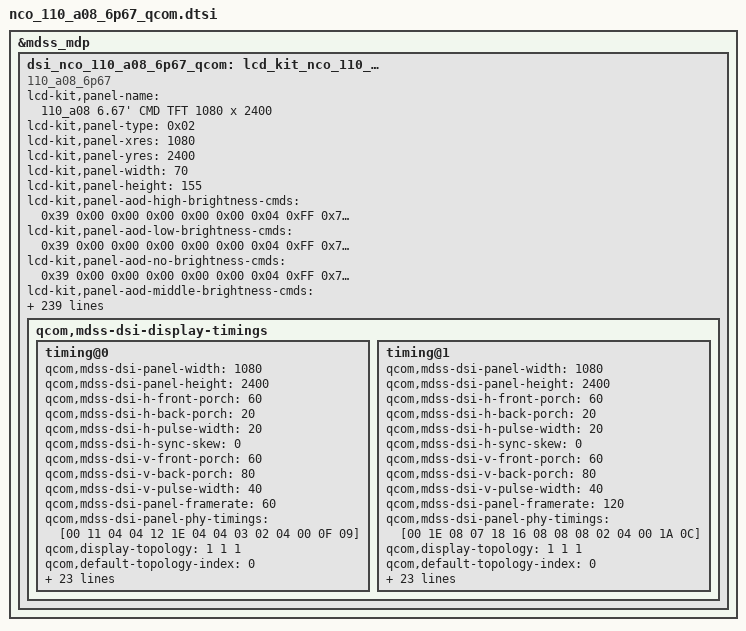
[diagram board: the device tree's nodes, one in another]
/* Copyright (c) 2013, The Linux Foundation. All rights reserved.
 *
 * This program is free software; you can redistribute it and/or modify
 * it under the terms of the GNU General Public License version 2 and
 * only version 2 as published by the Free Software Foundation.
 *
 * This program is distributed in the hope that it will be useful,
 * but WITHOUT ANY WARRANTY; without even the implied warranty of
 * MERCHANTABILITY or FITNESS FOR A PARTICULAR PURPOSE.  See the
 * GNU General Public License for more details.
 */

/*-------------------------------------------------------------------------
 * This file is autogenerated file using gcdb parser. Please do not edit it.
 * Update input XML file to add a new entry or update variable in this file
 * VERSION = 1.1
 *-----------------------------------------------------------------------*/
&mdss_mdp {
	dsi_nco_110_a08_6p67_qcom: lcd_kit_nco_110_a08_6p67_qcom {
		compatible = "110_a08_6p67";
		lcd-kit,panel-name = "110_a08 6.67' CMD TFT 1080 x 2400";
		lcd-kit,panel-type = <0x02>;
		lcd-kit,panel-xres = <1080>;
		lcd-kit,panel-yres = <2400>;
		lcd-kit,panel-width = <70>;
		lcd-kit,panel-height = <155>;
		lcd-kit,panel-aod-high-brightness-cmds = <0x39 0x00 0x00 0x00 0x00 0x00 0x04 0xFF 0x78 0x38 0x0C
		0x15 0x00 0x00 0x00 0x00 0x00 0x02 0xBE 0x00
		0x15 0x00 0x00 0x00 0x00 0x00 0x02 0x36 0x20
		0x15 0x00 0x00 0x00 0x00 0x00 0x02 0x34 0xF2
		0x39 0x01 0x00 0x00 0x00 0x00 0x04 0xFF 0x78 0x38 0x00>;
		lcd-kit,panel-aod-low-brightness-cmds = <0x39 0x00 0x00 0x00 0x00 0x00 0x04 0xFF 0x78 0x38 0x0C
		0x15 0x00 0x00 0x00 0x00 0x00 0x02 0xBE 0x02
		0x15 0x00 0x00 0x00 0x00 0x00 0x02 0x36 0x20
		0x15 0x00 0x00 0x00 0x00 0x00 0x02 0x34 0xF2
		0x39 0x01 0x00 0x00 0x00 0x00 0x04 0xFF 0x78 0x38 0x00>;
		lcd-kit,panel-aod-no-brightness-cmds = <0x39 0x00 0x00 0x00 0x00 0x00 0x04 0xFF 0x78 0x38 0x0C
		0x15 0x00 0x00 0x00 0x00 0x00 0x02 0x34 0xFF
		0x15 0x00 0x00 0x00 0x00 0x00 0x02 0x36 0xFF
		0x39 0x01 0x00 0x00 0x00 0x00 0x04 0xFF 0x78 0x38 0x00>;
		lcd-kit,panel-aod-middle-brightness-cmds = <0x39 0x00 0x00 0x00 0x00 0x00 0x04 0xFF 0x78 0x38 0x0C
		0x15 0x00 0x00 0x00 0x00 0x00 0x02 0xBE 0x01
		0x15 0x00 0x00 0x00 0x00 0x00 0x02 0x36 0x20
		0x15 0x00 0x00 0x00 0x00 0x00 0x02 0x34 0xF2
		0x39 0x01 0x00 0x00 0x00 0x00 0x04 0xFF 0x78 0x38 0x00>;
		lcd-kit,panel-aod-high-brightness-cmds-state = "dsi_lp_mode";
		lcd-kit,panel-aod-low-brightness-cmds-state = "dsi_lp_mode";
		lcd-kit,panel-aod-no-brightness-cmds-state = "dsi_lp_mode";
		lcd-kit,panel-aod-middle-brightness-cmds-state = "dsi_lp_mode";
		lcd-kit,pcd-check-reg-cmds = <0x01>;
		lcd-kit,check-reg-on-cmds = <0x06 0x01 0x00 0x00 0x0a 0x00 0x01 0x0a>;
		lcd-kit,check-reg-on-value = <0x9c>;
		lcd-kit,check-aod-reg-on-cmds = <0x06 0x01 0x00 0x00 0x0a 0x00 0x01 0x0a>;
		lcd-kit,check-aod-reg-on-value = <0xdc>;
		lcd-kit,check-reg-off-cmds = <0x06 0x01 0x00 0x00 0x0a 0x00 0x01 0x0a>;
		lcd-kit,check-reg-off-value = <0x08>;
		lcd-kit,check-reg-on-cmds-state = "dsi_lp_mode";
		lcd-kit,check-aod-reg-on-cmds-state = "dsi_lp_mode";
		lcd-kit,check-reg-off-cmds-state = "dsi_lp_mode";
		lcd-kit,pcd-check-reg-value = <0x01>;
		lcd-kit,pcd-errflag-check-support = <0>;
		lcd-kit,checksum-enable-cmds = <0x39 0x01 0x00 0x00 0x14 0x00 0x05 0xFF 0xAA 0x55 0xA5 0x80
		0x15 0x01 0x00 0x00 0x0a 0x00 0x02 0xF2 0x03>;
		lcd-kit,checksum-enable-cmds-state = "dsi_lp_mode";
		lcd-kit,checksum-disable-cmds = <0x39 0x01 0x00 0x00 0x14 0x00 0x05 0xFF 0xAA 0x55 0xA5 0x80
		0x15 0x01 0x00 0x00 0x0a 0x00 0x02 0xF2 0x00>;
		lcd-kit,checksum-disable-cmds-state = "dsi_lp_mode";
		lcd-kit,checksum-cmds = <0x39 0x01 0x00 0x00 0x14 0x00 0x05 0xFF 0xAA 0x55 0xA5 0x80
		0x15 0x01 0x00 0x00 0x0a 0x00 0x02 0x6F 0x01
		0x14 0x01 0x00 0x00 0x0a 0x00 0x08 0xF2 0x00 0x00 0x00 0x00 0x00 0x00 0x00>;
		lcd-kit,checksum-cmds-state = "dsi_lp_mode";
		lcd-kit,checksum-value = <0x06 0xf2 0x7d 0x83 0x91 0xe7 0x4c 0x2a
		0xba 0xeb 0x79 0x7c 0xe4 0xb4 0xcb 0x62
		0x97 0x89 0xd0 0x7a 0xc4 0xee 0xf7 0x69>;
		lcd-kit,hor-line-cmds = <0x39 0x01 0x00 0x00 0x00 0x00 0x04 0xFF 0x78 0x38 0x00
		0x05 0x01 0x00 0x00 0x64 0x00 0x01 0x28
		0x39 0x01 0x00 0x00 0x00 0x00 0x04 0xFF 0x78 0x38 0x05
		0x15 0x01 0x00 0x00 0x00 0x00 0x02 0x2E 0x4D
		0x15 0x01 0x00 0x00 0x00 0x00 0x02 0x34 0x4D
		0x15 0x01 0x00 0x00 0x00 0x00 0x02 0x73 0x0B
		0x15 0x01 0x00 0x00 0x00 0x00 0x02 0x77 0x0B
		0x15 0x01 0x00 0x00 0x00 0x00 0x02 0x03 0x4E
		0x15 0x01 0x00 0x00 0x00 0x00 0x02 0x20 0xAB
		0x15 0x01 0x00 0x00 0x00 0x00 0x02 0x23 0xAE
		0x39 0x01 0x00 0x00 0x00 0x00 0x04 0xFF 0x78 0x38 0x00
		0x39 0x01 0x00 0x00 0x00 0x00 0x03 0x51 0x0D 0xBB
		0x05 0x01 0x00 0x00 0x78 0x00 0x01 0x11
		0x05 0x01 0x00 0x00 0x64 0x00 0x01 0x29>;
		lcd-kit,hor-line-cmds-state = "dsi_lp_mode";
		lcd-kit,pcd-read-cmds = <0x39 0x01 0x00 0x00 0x00 0x00 0x04 0xFF 0x78 0x38 0x1B
		0x15 0x01 0x00 0x00 0x00 0x00 0x02 0xF1 0x10
		0x06 0x01 0x00 0x00 0x00 0x00 0x01 0xF7
		0x39 0x01 0x00 0x00 0x00 0x00 0x04 0xFF 0x78 0x38 0x00
		0x39 0x01 0x00 0x00 0x00 0x00 0x04 0xFF 0x78 0x38 0x1B
		0x15 0x01 0x00 0x00 0x00 0x00 0x02 0xF1 0x00
		0x39 0x01 0x00 0x00 0x00 0x00 0x04 0xFF 0x78 0x38 0x00>;
		lcd-kit,pcd-read-cmds-state  = "dsi_lp_mode";
		lcd-kit,vtc-line-cmds = <0x39 0x01 0x00 0x00 0x00 0x00 0x04 0xFF 0x78 0x38 0x00
		0x05 0x01 0x00 0x00 0x64 0x00 0x01 0x28
		0x39 0x01 0x00 0x00 0x00 0x00 0x04 0xFF 0x78 0x38 0x05
		0x15 0x01 0x00 0x00 0x00 0x00 0x02 0xA2 0x02
		0x39 0x01 0x00 0x00 0x00 0x00 0x04 0xFF 0x78 0x38 0x14
		0x15 0x01 0x00 0x00 0x00 0x00 0x02 0x00 0x00
		0x39 0x01 0x00 0x00 0x00 0x00 0x04 0xFF 0x78 0x38 0x17
		0x15 0x01 0x00 0x00 0x00 0x00 0x02 0x20 0x00
		0x39 0x01 0x00 0x00 0x00 0x00 0x04 0xFF 0x78 0x38 0x00
		0x39 0x01 0x00 0x00 0x00 0x00 0x03 0x51 0x0D 0xBB
		0x05 0x01 0x00 0x00 0x78 0x00 0x01 0x11
		0x05 0x01 0x00 0x00 0x64 0x00 0x01 0x29>;
		lcd-kit,vtc-line-cmds-state  = "dsi_lp_mode";
		lcd-kit,ddic-lv-det-enter1-cmds = <0x39 0x01 0x00 0x00 0x00 0x00 0x04 0xFF 0x78 0x38 0x1C
		0x15 0x01 0x00 0x00 0x00 0x00 0x02 0x6A 0xFF
		0x39 0x01 0x00 0x00 0x00 0x00 0x04 0xFF 0x78 0x38 0x00>;
		lcd-kit,ddic-lv-det-enter1-cmds-state  = "dsi_lp_mode";
		lcd-kit,ddic-lv-det-enter2-cmds = <0x39 0x01 0x00 0x00 0x00 0x00 0x04 0xFF 0x78 0x38 0x1C
		0x15 0x01 0x00 0x00 0x00 0x00 0x02 0x6A 0xFF
		0x39 0x01 0x00 0x00 0x00 0x00 0x04 0xFF 0x78 0x38 0x00>;
		lcd-kit,ddic-lv-det-enter2-cmds-state  = "dsi_lp_mode";
		lcd-kit,ddic-lv-det-enter3-cmds = <0x39 0x01 0x00 0x00 0x00 0x00 0x04 0xFF 0x78 0x38 0x1C
		0x15 0x01 0x00 0x00 0x00 0x00 0x02 0x6A 0xFF
		0x39 0x01 0x00 0x00 0x00 0x00 0x04 0xFF 0x78 0x38 0x00>;
		lcd-kit,ddic-lv-det-enter3-cmds-state  = "dsi_lp_mode";
		lcd-kit,ddic-lv-det-enter4-cmds = <0x39 0x01 0x00 0x00 0x00 0x00 0x04 0xFF 0x78 0x38 0x1C
		0x15 0x01 0x00 0x00 0x00 0x00 0x02 0x6A 0xFF
		0x39 0x01 0x00 0x00 0x00 0x00 0x04 0xFF 0x78 0x38 0x00>;
		lcd-kit,ddic-lv-det-enter4-cmds-state  = "dsi_lp_mode";
		lcd-kit,ddic-lv-det-rd1-cmds = <0x06 0x01 0x00 0x00 0x00 0x00 0x01 0x0a>;
		lcd-kit,ddic-lv-det-rd1-cmds-state  = "dsi_lp_mode";
		lcd-kit,ddic-lv-det-rd2-cmds = <0x06 0x01 0x00 0x00 0x00 0x00 0x01 0x0a>;
		lcd-kit,ddic-lv-det-rd2-cmds-state  = "dsi_lp_mode";
		lcd-kit,ddic-lv-det-rd3-cmds = <0x06 0x01 0x00 0x00 0x00 0x00 0x01 0x0a>;
		lcd-kit,ddic-lv-det-rd3-cmds-state  = "dsi_lp_mode";
		lcd-kit,ddic-lv-det-rd4-cmds = <0x06 0x01 0x00 0x00 0x00 0x00 0x01 0x0a>;
		lcd-kit,ddic-lv-det-rd4-cmds-state  = "dsi_lp_mode";
		lcd-kit,ddic-lv-det-value1 = <0x9c>;
		lcd-kit,ddic-lv-det-value2 = <0x9c>;
		lcd-kit,ddic-lv-det-value3 = <0x9c>;
		lcd-kit,ddic-lv-det-value4 = <0x9c>;
		lcd-kit,bl-after-frame = <0>;
		lcd-kit,cmd-async-support = <0>;
		lcd-kit,ap-aod-support = <1>;
		lcd-kit,left-time-to-te-us = <28667>;
		lcd-kit,right-time-to-te-us = <29667>;
		lcd-kit,te-interval-time-us = <16667>;
		lcd-kit,oneside-mode-support = <0>;
		lcd-kit,color-aod-detect-support = <0>;
		lcd-kit,elvdd-detect-support = <0>;
		lcd-kit,elvdd-detect-type = <2>;
		lcd-kit,elvdd-detect-value = <1>;
		lcd-kit,elvdd-delay = <50>;
		lcd-kit,elvdd-detect-gpio = <104>;
		lcd-kit,check-reg-on-support = <0>;
		lcd-kit,check-reg-on-support-dsm-report = <0>;
		lcd-kit,check-aod-reg-on-support = <0>;
		lcd-kit,check-aod-reg-on-support-dsm-report = <0>;
		lcd-kit,check-reg-off-support = <0>;
		lcd-kit,check-reg-off-support-dsm-report = <0>;
		lcd-kit,checksum-support = <0>;
		lcd-kit,pcd-cmds-support = <1>;
		lcd-kit,pcd-check-reg-value-compare-mode = <1>;
		lcd-kit,vtc-line-support = <1>;
		lcd-kit,ddic-lv-det-support = <1>;
		lcd-kit,hor-line-support = <1>;
		lcd-kit,hor-line-duration = <600>;
		lcd-kit,vtc-line-no-reset = <1>;
		qcom,mdss-dsi-panel-type = "dsi_cmd_mode";
		qcom,mdss-pan-physical-width-dimension = <70>;
		qcom,mdss-pan-physical-height-dimension = <155>;
		qcom,dsi-ctrl-num = <0>;
		qcom,dsi-phy-num = <0>;
		qcom,panel-supply-entries = <&dsi_panel_pwr_supply>;
		qcom,mdss-dsi-virtual-channel-id = <0>;
		qcom,mdss-dsi-h-sync-pulse = <0>;
		qcom,mdss-dsi-bllp-eof-power-mode;
		qcom,mdss-dsi-bllp-power-mode;
		qcom,mdss-dsi-dma-schedule-line = <1>;
		qcom,mdss-dsi-bpp = <24>;
		qcom,mdss-dsi-color-order = "rgb_swap_rgb";
		qcom,mdss-dsi-underflow-color = <0xff>;
		qcom,mdss-dsi-border-color = <0>;
		qcom,mdss-dsi-traffic-mode = "burst_mode";
		qcom,mdss-dsi-lane-map = "lane_map_0123";
		qcom,mdss-dsi-lane-0-state;
		qcom,mdss-dsi-lane-1-state;
		qcom,mdss-dsi-lane-2-state;
		qcom,mdss-dsi-lane-3-state;
		qcom,mdss-dsi-mdp-trigger = "none";
		qcom,mdss-dsi-dma-trigger = "trigger_sw";
		qcom,mdss-dsi-te-pin-select = <1>;
		qcom,mdss-dsi-wr-mem-start = <0x2c>;
		qcom,mdss-dsi-wr-mem-continue = <0x3c>;
		qcom,mdss-dsi-te-dcs-command = <1>;
		qcom,mdss-dsi-te-check-enable;
		qcom,mdss-dsi-te-using-te-pin;
		qcom,dsi-panel-gpio-address = <0x0F100000 0x1000>;
		qcom,dsi-panel-gpio-pins = <12 93 80>;
		qcom,dsi-panel-gpio-names = "reg-gpio", "reset-gpio", "platform-te-gpio";
		qcom,mdss-dsi-t-clk-post = <0>;
		qcom,mdss-dsi-t-clk-pre = <0>;
		qcom,dsi-select-clocks = "mux_byte_clk0", "mux_pixel_clk0";
		qcom,mdss-dsi-stream = <0>;
		lcd-kit,check-thread-support = <0>;
		lcd-kit,check-time-period = <5000>;
		lcd-kit,check-fold-support = <0>;
		lcd-kit,fold-low-power-support = <0>;
		lcd-kit,fold-height = <0>;
		lcd-kit,unfold-height = <0>;
		lcd-kit,power-support = <0>;
		lcd-kit,three-stage-poweron = <1>;
		lcd-kit,fold-lp-time = <0>;
		lcd-kit,fold-nolp-time = <0>;
		qcom,sublinks-count = <2>;
		qcom,lanes-per-sublink = <2>;
		qcom,mdss-dsi-panel-hdr-color-primaries = <14500 15500 32000 17000 15500 30000 8000 3000>;
		qcom,mdss-dsi-panel-peak-brightness = <4200000>;
		qcom,mdss-dsi-panel-blackness-level = <3230>;
		qcom,dynamic-mode-switch-enabled;
		qcom,dynamic-mode-switch-type = "dynamic-resolution-switch-immediate";
		qcom,mdss-dsi-bl-pmic-control-type = "bl_ctrl_dcs";
		qcom,mdss-dsi-bl-min-level = <1>;
		qcom,mdss-dsi-bl-max-level = <10000>;
		qcom,esd-check-enabled;
		qcom,mdss-dsi-panel-status-command = [06 01 00 00 00 00 01 0A];
		qcom,mdss-dsi-panel-status-command-state = "dsi_lp_mode";
		qcom,mdss-dsi-panel-status-check-mode = "reg_read";
		qcom,mdss-dsi-panel-status-read-length = <1>;
		qcom,mdss-dsi-panel-status-value = <0x9C>;
		lcd-kit,power-on-stage = <2 1 3
				1 1 1
				9 1 15>;
		lcd-kit,lp-on-stage = <5 1 5
				5 0 2
				5 1 30
				7 1 0
				6 1 0
				8 1 0>;
		lcd-kit,lp-off-stage = <0 0 0>;
		lcd-kit,power-off-stage = <7 0 0
				6 0 0
				8 0 0
				5 0 2
				9 0 1
				1 0 2
				2 0 1>;
		lcd-kit,only-power-off-stage = <0 0 0>;
		lcd-kit,pt-support = <1>;
		lcd-kit,panel-on-always-reset = <0>;
		lcd-kit,lcd-vci = <1 13 3000000 3000000 3000000 10000 80>;
		lcd-kit,lcd-iovcc = <1 12 1800000 1800000 1800000 60700 80>;
		lcd-kit,lcd-vdd = <1 16 1250000 1250000 1250000 30000 80>;
		lcd-kit,lcd-reset = <2 93 0>;
		lcd-kit,lcd-vci-name = "vdd";
		lcd-kit,lcd-iovcc-name = "vddio";
		lcd-kit,lcd-vdd-name = "ddic";
		lcd-kit,project-id-support = <0>;
		lcd-kit,default-project-id = "B2359S2920";
		lcd-kit,sn-code-support = <1>;
		lcd-kit,oem-info-support = <1>;
		lcd-kit,oem-barcode-2d-support = <1>;
		lcd-kit,oem-barcode-2d-num-offset = <0>;
		lcd-kit,barcode-2d-cmds = <0x39 0x01 0x00 0x00 0x00 0x00 0x04 0xFF 0x78 0x38 0x0F
                   0x06 0x01 0x00 0x00 0x00 0x00 0x01 0x00
                   0x06 0x01 0x00 0x00 0x00 0x00 0x01 0x01
                   0x06 0x01 0x00 0x00 0x00 0x00 0x01 0x02
                   0x06 0x01 0x00 0x00 0x00 0x00 0x01 0x03
                   0x06 0x01 0x00 0x00 0x00 0x00 0x01 0x04
                   0x06 0x01 0x00 0x00 0x00 0x00 0x01 0x05
                   0x06 0x01 0x00 0x00 0x00 0x00 0x01 0x06
                   0x06 0x01 0x00 0x00 0x00 0x00 0x01 0x07
                   0x06 0x01 0x00 0x00 0x00 0x00 0x01 0x08
                   0x06 0x01 0x00 0x00 0x00 0x00 0x01 0x09
                   0x06 0x01 0x00 0x00 0x00 0x00 0x01 0x0A
                   0x06 0x01 0x00 0x00 0x00 0x00 0x01 0x0B
                   0x06 0x01 0x00 0x00 0x00 0x00 0x01 0x0C
                   0x06 0x01 0x00 0x00 0x00 0x00 0x01 0x0D
                   0x06 0x01 0x00 0x00 0x00 0x00 0x01 0x0E
                   0x06 0x01 0x00 0x00 0x00 0x00 0x01 0x0F
                   0x06 0x01 0x00 0x00 0x00 0x00 0x01 0x10
                   0x06 0x01 0x00 0x00 0x00 0x00 0x01 0x11
                   0x06 0x01 0x00 0x00 0x00 0x00 0x01 0x12
                   0x06 0x01 0x00 0x00 0x00 0x00 0x01 0x13
                   0x06 0x01 0x00 0x00 0x00 0x00 0x01 0x14
                   0x39 0x01 0x00 0x00 0x00 0x00 0x04 0xFF 0x78 0x38 0x00>;
		lcd-kit,barcode-2d-cmds-state = "dsi_lp_mode";
		lcd-kit,panel-getblmaxnit-type = <0>;
		lcd-kit,panel-blmaxnit-min-value = <400>;
		lcd-kit,inversion-support = <0>;
		lcd-kit,panel-gpio-offset = <336>;
		lcd-kit,finger-unlock-state-support = <0>;
		lcd-kit,finger-handle-esd-support = <1>;
		lcd-kit,esd-reg-te-check = <0>;
		lcd-kit,dump-support = <0>;
		lcd-kit,underflow-support = <1>;
		lcd-kit,panel-bl-max-nit = <450>;
		lcd-kit,panel-bl-min = <18>;
		lcd-kit,panel-bl-max = <10000>;
		lcd-kit,panel-bl-def = <2047>;
		lcd-kit,check-reg-support = <0>;
		lcd-kit,thp-proximity-support = <0>;
		lcd-kit,proximity-reset-delay-min = <65>;
		lcd-kit,backlight-cmds = <0x39 0x01 0x00 0x00 0x00 0x00 0x03 0x51 0x00 0x00>;
		lcd-kit,backlight-cmds-state = "dsi_lp_mode";
		lcd-kit,backlight-order = <0>;
		lcd-kit,backlight-need-sync = <0>;
		lcd-kit,fps-support = <1>;
		lcd-kit,default-fps = <60>;
		lcd-kit,panel-support-fps-list = <60 120>;
		lcd-kit,fps-60-cmd = "vndservice call display.qservice 25 i32 0 i32 0";
		lcd-kit,fps-90-cmd = "vndservice call display.qservice 25 i32 2 i32 0";
		lcd-kit,fps-120-cmd = "vndservice call display.qservice 25 i32 1 i32 0";
		qcom,mdss-dsi-display-timings {
			timing@0 {
				qcom,mdss-dsi-panel-width = <1080>;
				qcom,mdss-dsi-panel-height = <2400>;
				qcom,mdss-dsi-h-front-porch = <60>;
				qcom,mdss-dsi-h-back-porch = <20>;
				qcom,mdss-dsi-h-pulse-width = <20>;
				qcom,mdss-dsi-h-sync-skew = <0>;
				qcom,mdss-dsi-v-front-porch = <60>;
				qcom,mdss-dsi-v-back-porch = <80>;
				qcom,mdss-dsi-v-pulse-width = <40>;
				qcom,mdss-dsi-panel-framerate = <60>;
				qcom,mdss-dsi-panel-phy-timings= [00 11 04 04 12 1E 04
			04 03 02 04 00 0F 09];
				qcom,display-topology  = <1 1 1>;
				qcom,default-topology-index  = <0>;
				qcom,mdss-dsi-on-command = [39 01 00 00 00 00 04 FF 78 38 08
		15 01 00 00 00 00 02 45 4C
		39 01 00 00 00 00 04 FF 78 38 01
		15 01 00 00 00 00 02 5A 50
		15 01 00 00 00 00 02 65 50
		39 01 00 00 00 00 04 FF 78 38 02
		15 01 00 00 00 00 02 32 76
		15 01 00 00 00 00 02 34 76
		15 01 00 00 00 00 02 36 DC
		15 01 00 00 00 00 02 3E 80
		39 01 00 00 00 00 04 FF 78 38 05
		15 01 00 00 00 00 02 11 04
		39 01 00 00 00 00 04 FF 78 38 06
		15 01 00 00 00 00 02 C9 A0
		39 01 00 00 00 00 04 FF 78 38 08
		15 01 00 00 00 00 02 96 3F
		39 01 00 00 00 00 04 FF 78 38 0F
		15 01 00 00 00 00 02 6E 13
		15 01 00 00 00 00 02 92 00
		15 01 00 00 00 00 02 93 D1
		15 01 00 00 00 00 02 94 11
		15 01 00 00 00 00 02 95 10
		15 01 00 00 00 00 02 96 00
		15 01 00 00 00 00 02 9E 00
		15 01 00 00 00 00 02 A1 13
		15 01 00 00 00 00 02 A2 13
		15 01 00 00 00 00 02 A3 F3
		15 01 00 00 00 00 02 A4 00
		15 01 00 00 00 00 02 A6 63
		15 01 00 00 00 00 02 A7 26
		15 01 00 00 00 00 02 A9 3C
		15 01 00 00 00 00 02 AA 08
		15 01 00 00 00 00 02 D8 46
		15 01 00 00 00 00 02 D9 80
		15 01 00 00 00 00 02 DA 11
		15 01 00 00 00 00 02 DB 13
		15 01 00 00 00 00 02 DC D1
		15 01 00 00 00 00 02 DD C0
		15 01 00 00 00 00 02 DE 08
		15 01 00 00 00 00 02 DF 11
		15 01 00 00 00 00 02 E0 13
		15 01 00 00 00 00 02 E1 D1
		15 01 00 00 00 00 02 E2 C0
		15 01 00 00 00 00 02 E3 08
		15 01 00 00 00 00 02 E4 11
		39 01 00 00 00 00 04 FF 78 38 11
		15 01 00 00 00 00 02 71 50
		15 01 00 00 00 00 02 77 50
		39 01 00 00 00 00 04 FF 78 38 19
		15 01 00 00 00 00 02 E0 08
		39 01 00 00 00 00 04 FF 78 38 02
		15 01 00 00 00 00 02 38 32
		15 01 00 00 00 00 02 17 40
		39 01 00 00 00 00 04 FF 78 38 0A
		15 01 00 00 00 00 02 30 0F
		39 01 00 00 00 00 04 FF 78 38 0C
		15 01 00 00 00 00 02 BE 00
		39 01 00 00 00 00 04 FF 78 38 00
		15 01 00 00 00 00 02 95 10
		39 01 00 00 00 00 04 FF 78 38 00
		15 01 00 00 00 00 02 53 20
		15 01 00 00 00 00 02 35 00
		39 01 00 00 00 00 04 FF 78 38 07
		15 01 00 00 00 00 02 29 01
		39 01 00 00 00 00 04 FF 78 38 08
		15 01 00 00 00 00 02 57 25
		39 01 00 00 00 00 04 FF 78 38 06
		15 01 00 00 00 00 02 C6 01
		39 01 00 00 00 00 04 FF 78 38 00
		39 01 00 00 00 00 03 51 00 01
		05 01 00 00 78 00 01 11
		05 01 00 00 28 00 01 29];
				qcom,mdss-dsi-on-command-state = "dsi_lp_mode";
				qcom,mdss-dsi-off-command = [39 01 00 00 00 00 04 FF 78 38 00
		05 01 00 00 3C 00 01 28
		05 01 00 00 50 00 01 10];
				qcom,mdss-dsi-off-command-state = "dsi_lp_mode";
				qcom,compression-mode = "dsc";
				qcom,mdss-dsc-slice-height = <12>;
				qcom,mdss-dsc-slice-width = <1080>;
				qcom,mdss-dsc-slice-per-pkt = <1>;
				qcom,mdss-dsc-bit-per-component = <10>;
				qcom,mdss-dsc-bit-per-pixel = <8>;
				qcom,mdss-dsc-block-prediction-enable;
				qcom,mdss-dsi-timing-switch-command = [39 01 00 00 00 00 04 FF 78 38 02
		15 01 00 00 11 00 02 38 32
		39 01 00 00 00 00 04 FF 78 38 00];
				qcom,mdss-dsi-timing-switch-command-state = "dsi_lp_mode";
				qcom,mdss-dsi-lp1-command = [39 00 00 00 00 00 04 FF 78 38 0C
		15 00 00 00 00 00 02 34 FF
		15 00 00 00 00 00 02 36 FF
		39 00 00 00 00 00 04 FF 78 38 00
		05 01 00 00 00 00 01 39];
				qcom,mdss-dsi-lp1-command-state = "dsi_lp_mode";
				qcom,mdss-dsi-nolp-command = [39 00 00 00 00 00 04 FF 78 38 0C
		15 00 00 00 00 00 02 34 FF
		15 00 00 00 00 00 02 36 FF
		39 00 00 00 00 00 04 FF 78 38 00
		05 01 00 00 3C 00 01 38];
				qcom,mdss-dsi-nolp-command-state = "dsi_lp_mode";
			};
			timing@1 {
				qcom,mdss-dsi-panel-width = <1080>;
				qcom,mdss-dsi-panel-height = <2400>;
				qcom,mdss-dsi-h-front-porch = <60>;
				qcom,mdss-dsi-h-back-porch = <20>;
				qcom,mdss-dsi-h-pulse-width = <20>;
				qcom,mdss-dsi-h-sync-skew = <0>;
				qcom,mdss-dsi-v-front-porch = <60>;
				qcom,mdss-dsi-v-back-porch = <80>;
				qcom,mdss-dsi-v-pulse-width = <40>;
				qcom,mdss-dsi-panel-framerate = <120>;
				qcom,mdss-dsi-panel-phy-timings= [00 1E 08 07 18 16 08
			08 08 02 04 00 1A 0C];
				qcom,display-topology  = <1 1 1>;
				qcom,default-topology-index  = <0>;
				qcom,mdss-dsi-on-command = [39 01 00 00 00 00 04 FF 78 38 08
		15 01 00 00 00 00 02 45 4C
		39 01 00 00 00 00 04 FF 78 38 01
		15 01 00 00 00 00 02 5A 50
		15 01 00 00 00 00 02 65 50
		39 01 00 00 00 00 04 FF 78 38 02
		15 01 00 00 00 00 02 32 76
		15 01 00 00 00 00 02 34 76
		15 01 00 00 00 00 02 36 DC
		15 01 00 00 00 00 02 3E 80
		39 01 00 00 00 00 04 FF 78 38 05
		15 01 00 00 00 00 02 11 04
		39 01 00 00 00 00 04 FF 78 38 06
		15 01 00 00 00 00 02 C9 A0
		39 01 00 00 00 00 04 FF 78 38 08
		15 01 00 00 00 00 02 96 3F
		39 01 00 00 00 00 04 FF 78 38 0F
		15 01 00 00 00 00 02 6E 13
		15 01 00 00 00 00 02 92 00
		15 01 00 00 00 00 02 93 D1
		15 01 00 00 00 00 02 94 11
		15 01 00 00 00 00 02 95 10
		15 01 00 00 00 00 02 96 00
		15 01 00 00 00 00 02 9E 00
		15 01 00 00 00 00 02 A1 13
		15 01 00 00 00 00 02 A2 13
		15 01 00 00 00 00 02 A3 F3
		15 01 00 00 00 00 02 A4 00
		15 01 00 00 00 00 02 A6 63
		15 01 00 00 00 00 02 A7 26
		15 01 00 00 00 00 02 A9 3C
		15 01 00 00 00 00 02 AA 08
		15 01 00 00 00 00 02 D8 46
		15 01 00 00 00 00 02 D9 80
		15 01 00 00 00 00 02 DA 11
		15 01 00 00 00 00 02 DB 13
		15 01 00 00 00 00 02 DC D1
		15 01 00 00 00 00 02 DD C0
		15 01 00 00 00 00 02 DE 08
		15 01 00 00 00 00 02 DF 11
		15 01 00 00 00 00 02 E0 13
		15 01 00 00 00 00 02 E1 D1
		15 01 00 00 00 00 02 E2 C0
		15 01 00 00 00 00 02 E3 08
		15 01 00 00 00 00 02 E4 11
		39 01 00 00 00 00 04 FF 78 38 11
		15 01 00 00 00 00 02 71 50
		15 01 00 00 00 00 02 77 50
		39 01 00 00 00 00 04 FF 78 38 19
		15 01 00 00 00 00 02 E0 08
		39 01 00 00 00 00 04 FF 78 38 02
		15 01 00 00 00 00 02 38 31
		15 01 00 00 00 00 02 17 40
		39 01 00 00 00 00 04 FF 78 38 0A
		15 01 00 00 00 00 02 30 0F
		39 01 00 00 00 00 04 FF 78 38 0C
		15 01 00 00 00 00 02 BE 00
		39 01 00 00 00 00 04 FF 78 38 00
		15 01 00 00 00 00 02 95 10
		39 01 00 00 00 00 04 FF 78 38 00
		15 01 00 00 00 00 02 53 20
		15 01 00 00 00 00 02 35 00
		39 01 00 00 00 00 04 FF 78 38 07
		15 01 00 00 00 00 02 29 01
		39 01 00 00 00 00 04 FF 78 38 08
		15 01 00 00 00 00 02 57 25
		39 01 00 00 00 00 04 FF 78 38 06
		15 01 00 00 00 00 02 C6 01
		39 01 00 00 00 00 04 FF 78 38 00
		39 01 00 00 00 00 03 51 00 01
		05 01 00 00 78 00 01 11
		05 01 00 00 28 00 01 29];
				qcom,mdss-dsi-on-command-state = "dsi_lp_mode";
				qcom,mdss-dsi-off-command = [39 01 00 00 00 00 04 FF 78 38 00
		05 01 00 00 3C 00 01 28
		05 01 00 00 50 00 01 10];
				qcom,mdss-dsi-off-command-state = "dsi_lp_mode";
				qcom,compression-mode = "dsc";
				qcom,mdss-dsc-slice-height = <12>;
				qcom,mdss-dsc-slice-width = <1080>;
				qcom,mdss-dsc-slice-per-pkt = <1>;
				qcom,mdss-dsc-bit-per-component = <10>;
				qcom,mdss-dsc-bit-per-pixel = <8>;
				qcom,mdss-dsc-block-prediction-enable;
				qcom,mdss-dsi-timing-switch-command = [39 01 00 00 00 00 04 FF 78 38 02
		15 01 00 00 00 00 02 38 31
		39 01 00 00 00 00 04 FF 78 38 00];
				qcom,mdss-dsi-timing-switch-command-state = "dsi_lp_mode";
				qcom,mdss-dsi-lp1-command = [39 00 00 00 00 00 04 FF 78 38 0C
		15 00 00 00 00 00 02 34 FF
		15 00 00 00 00 00 02 36 FF
		39 00 00 00 00 00 04 FF 78 38 02
		15 00 00 00 00 00 02 38 32
		39 00 00 00 00 00 04 FF 78 38 00
		05 01 00 00 00 00 01 39];
				qcom,mdss-dsi-lp1-command-state = "dsi_lp_mode";
				qcom,mdss-dsi-nolp-command = [39 00 00 00 00 00 04 FF 78 38 02
		15 00 00 00 00 00 02 38 31
		39 00 00 00 00 00 04 FF 78 38 0C
		15 00 00 00 00 00 02 34 FF
		15 00 00 00 00 00 02 36 FF
		39 00 00 00 00 00 04 FF 78 38 00
		05 01 00 00 3C 00 01 38];
				qcom,mdss-dsi-nolp-command-state = "dsi_lp_mode";
			};
		};
    };
};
